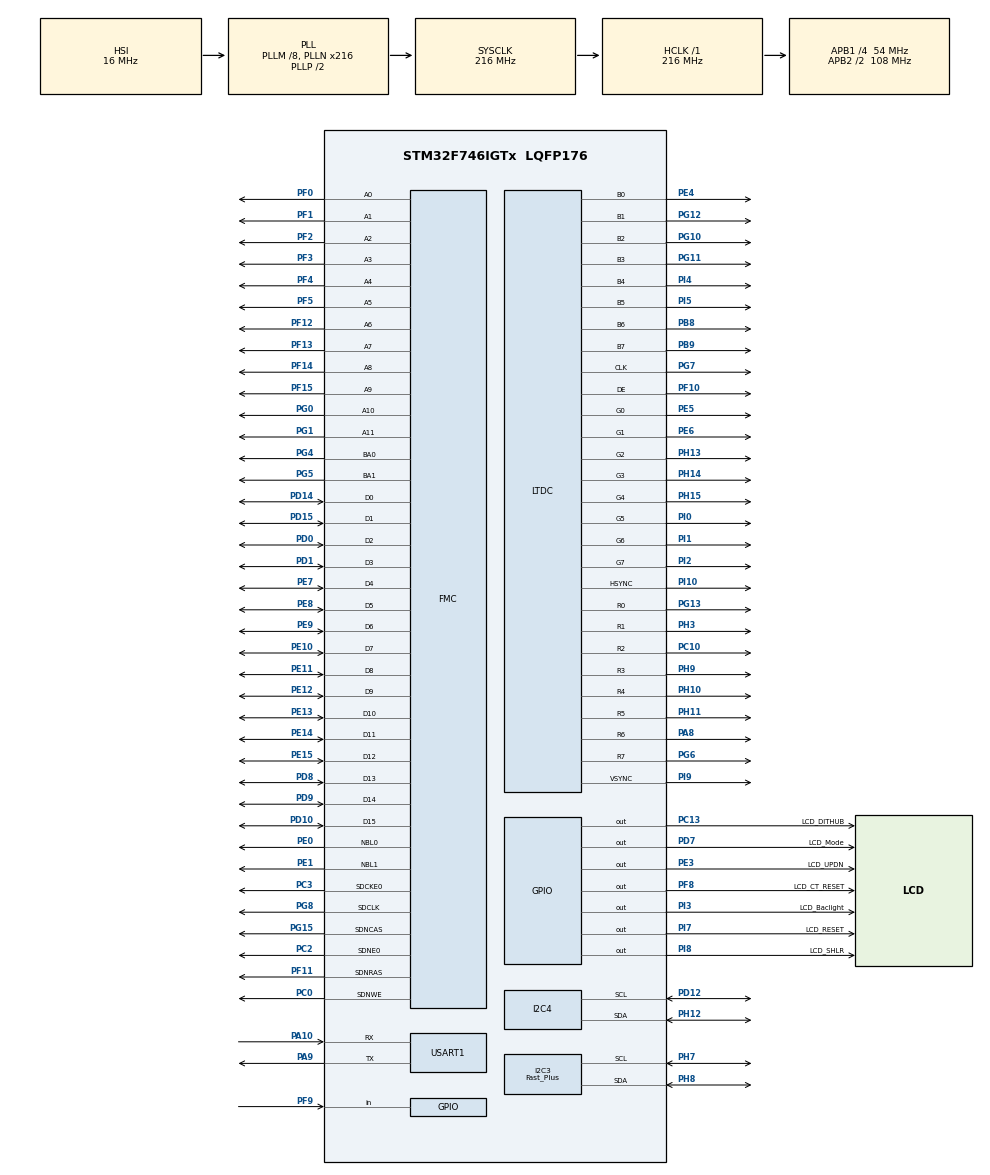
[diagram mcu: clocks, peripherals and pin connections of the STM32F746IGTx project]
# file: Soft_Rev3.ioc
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SH.FMC_D7_DA7.0=FMC_D7,sd-16b-d1
VP_SYS_VS_tim6.Mode=TIM6
FMC.SDClockPeriod2=FMC_SDRAM_CLOCK_PERIOD_2
PH12.Signal=I2C4_SDA
FMC.RCDDelay1=2
FMC.SDClockPeriod1=FMC_SDRAM_CLOCK_PERIOD_2
SH.FMC_A0.0=FMC_A0,12b-sda1
NVIC.TIM6_DAC_IRQn=true\:0\:0\:false\:false\:true\:false\:false\:true
PG8.Signal=FMC_SDCLK
PG4.Signal=FMC_A14_BA0
PG0.Signal=FMC_A10
FMC.LoadToActiveDelay1=2
SH.FMC_D5_DA5.0=FMC_D5,sd-16b-d1
VP_STMicroelectronics.X-CUBE-TOUCHGFX_VS_GraphicsJjApplication_4.16.0.Mode=GraphicsJjApplication
PG6.Mode=RGB888
PG13.Signal=LTDC_R0
PF8.PinState=GPIO_PIN_SET
LTDC.Red=0
RCC.SYSCLKSource=RCC_SYSCLKSOURCE_PLLCLK
SH.FMC_A15_BA1.0=FMC_BA1,FourSdramBanks1
SH.FMC_D9_DA9.0=FMC_D9,sd-16b-d1
STMicroelectronics.X-CUBE-TOUCHGFX.4.16.0.tgfx_hardware_accelerator=dma_2d
FREERTOS.configENABLE_FPU=1
SH.FMC_SDNWE.0=FMC_SDNWE,12b-sda1
PH9.Signal=LTDC_R3
I2C4.Timing=0x20404768
SH.FMC_D11_DA11.0=FMC_D11,sd-16b-d1
RCC.APB2TimFreq_Value=216000000
PH1/OSC_OUT.Signal=RCC_OSC_OUT
PC3.Signal=FMC_SDCKE0
PD0.Signal=FMC_D2_DA2
PD8.Signal=FMC_D13_DA13
PE5.Signal=LTDC_G0
PE1.Signal=FMC_NBL1
FREERTOS.configMINIMAL_STACK_SIZE=254
FMC.SelfRefreshTime1=4
LTDC.PixelFormat_L0=LTDC_PIXEL_FORMAT_RGB565
PF8.GPIO_ModeDefaultOutputPP=GPIO_MODE_OUTPUT_OD
PE9.Signal=FMC_D6_DA6
SH.FMC_A2.0=FMC_A2,12b-sda1
PI3.Signal=GPIO_Output
PA8.Signal=LTDC_R6
SH.FMC_D1_DA1.0=FMC_D1,sd-16b-d1
PF3.Signal=FMC_A3
FMC.WriteProtection1=FMC_SDRAM_WRITE_PROTECTION_DISABLE
PE10.Signal=FMC_D7_DA7
LTDC.HSync=16
PI7.PinState=GPIO_PIN_SET
Mcu.Package=LQFP176
PH10.GPIO_Speed=GPIO_SPEED_FREQ_VERY_HIGH
PB9.Signal=LTDC_B7
PI10.GPIO_Speed=GPIO_SPEED_FREQ_VERY_HIGH
PH12.Mode=I2C
NVIC.TimeBase=TIM6_DAC_IRQn
PH3.GPIO_Speed=GPIO_SPEED_FREQ_VERY_HIGH
PD12.Signal=I2C4_SCL
PI7.GPIO_PuPd=GPIO_PULLUP
PH11.Mode=RGB888
LTDC.Green=0
NVIC.TimeBaseIP=TIM6
PA10.Signal=USART1_RX
FMC.WriteRecoveryTime1=3
SH.FMC_A1.0=FMC_A1,12b-sda1
RCC.APB2CLKDivider=RCC_HCLK_DIV2
SH.FMC_SDCLK.0=FMC_SDCLK,12b-sda1
LTDC.VSync=8
PF14.Signal=FMC_A8
RCC.APB1TimFreq_Value=108000000
VP_DMA2D_VS_DMA2D.Mode=DMA2D_Activate
FMC.RowCycleDelay2=7
PF10.Mode=RGB888
FMC.RowCycleDelay1=7
PH8.Mode=I2C
PE6.GPIO_Speed=GPIO_SPEED_FREQ_VERY_HIGH
PA8.GPIO_Speed=GPIO_SPEED_FREQ_VERY_HIGH
PD15.Signal=FMC_D1_DA1
SH.FMC_D3_DA3.0=FMC_D3,sd-16b-d1
PG6.GPIO_Speed=GPIO_SPEED_FREQ_VERY_HIGH
PG12.Signal=LTDC_B1
SH.FMC_A4.0=FMC_A4,12b-sda1
PH15.Signal=LTDC_G4
FREERTOS.Tasks01=HardwareTask,24,512,StartHardwareTask,Default,NULL,Dynamic,NULL,NULL;TouchGFXTask,24,8192,StartGFXTask,Default,NULL,Dynamic,NULL,NULL
PH13.Signal=LTDC_G2
PI4.Mode=RGB888
PG5.Signal=FMC_A15_BA1
PC13.Signal=GPIO_Output
SH.FMC_D10_DA10.0=FMC_D10,sd-16b-d1
FREERTOS.configCHECK_FOR_STACK_OVERFLOW=2
PI10.Mode=RGB888
PC2.Signal=FMC_SDNE0
PD7.Signal=GPIO_Output
PD1.Signal=FMC_D3_DA3
STMicroelectronics.X-CUBE-TOUCHGFX.4.16.0.tgfx_buffering_strategy=Single
PC0.Signal=FMC_SDNWE
RCC.APB1CLKDivider=RCC_HCLK_DIV4
PI2.Mode=RGB888
PG10.Signal=LTDC_B2
PF8.GPIO_Label=LCD_CT_RESET
LTDC.ImageWidth_L0=1024
PD10.Signal=FMC_D15_DA15
SH.FMC_A3.0=FMC_A3,12b-sda1
PI8.GPIO_Label=LCD_SHLR
FMC.CASLatency1=FMC_SDRAM_CAS_LATENCY_3
PI0.GPIO_Speed=GPIO_SPEED_FREQ_VERY_HIGH
SH.FMC_D15_DA15.0=FMC_D15,sd-16b-d1
PH9.Mode=RGB888
PA9.Signal=USART1_TX
PH14.Mode=RGB888
PI7.Signal=GPIO_Output
FMC.ReadBurst1=FMC_SDRAM_RBURST_DISABLE
SH.FMC_A6.0=FMC_A6,12b-sda1
PE14.Signal=FMC_D11_DA11
LTDC.Blue_L0=0
PE6.Mode=RGB888
PE15.Signal=FMC_D12_DA12
PE8.Signal=FMC_D5_DA5
PI1.Signal=LTDC_G6
PI2.Signal=LTDC_G7
PE3.GPIO_PuPd=GPIO_PULLDOWN
PF13.Signal=FMC_A7
PA13.Mode=Serial_Wire
SH.FMC_SDNCAS.0=FMC_SDNCAS,12b-sda1
PI8.PinState=GPIO_PIN_SET
PD12.Mode=I2C
SH.FMC_A5.0=FMC_A5,12b-sda1
PG11.Mode=RGB888
LTDC.Alpha_L0=255
ProjectManager.HeapSize=0xF000
PG12.GPIO_Speed=GPIO_SPEED_FREQ_VERY_HIGH
PF9.Signal=GPIO_Input
STMicroelectronics.X-CUBE-TOUCHGFX.4.16.0.tgfx_vsync=vsync_ltdc
NVIC.PriorityGroup=NVIC_PRIORITYGROUP_4
PB8.Mode=RGB888
PE3.Signal=GPIO_Output
PC15/OSC32_OUT.Signal=RCC_OSC32_OUT
PA8.Mode=RGB888
PF4.Signal=FMC_A4
LTDC.Alpha0_L0=0
I2C3.I2C_Speed_Mode=I2C_Fast_Plus
Mcu.Family=STM32F7
PC3.Mode=SdramChipSelect1_1
LTDC.BlendingFactor1_L0=LTDC_BLENDING_FACTOR1_CA
SH.FMC_A8.0=FMC_A8,12b-sda1
RCC.CortexFreq_Value=216000000
PG6.Signal=LTDC_R7
PH14.Signal=LTDC_G3
PH10.Signal=LTDC_R4
SH.FMC_D14_DA14.0=FMC_D14,sd-16b-d1
LTDC.HBP=160
PC10.Signal=LTDC_R2
SH.FMC_NBL0.0=FMC_NBL0,Sd2ByteEnable1
SH.FMC_D6_DA6.0=FMC_D6,sd-16b-d1
PC14/OSC32_IN.Mode=LSE-External-Oscillator
PC10.GPIO_Speed=GPIO_SPEED_FREQ_VERY_HIGH
SH.FMC_A14_BA0.0=FMC_BA0,FourSdramBanks1
PH9.GPIO_Speed=GPIO_SPEED_FREQ_VERY_HIGH
SH.FMC_A11.0=FMC_A11,12b-sda1
PI9.GPIO_Speed=GPIO_SPEED_FREQ_VERY_HIGH
PC13.GPIO_Label=LCD_DITHUB
PI2.GPIO_Speed=GPIO_SPEED_FREQ_VERY_HIGH
PI5.Mode=RGB888
PG11.Signal=LTDC_B3
PG15.Signal=FMC_SDNCAS
ProjectManager.StackSize=0x400
VP_FREERTOS_VS_CMSIS_V2.Mode=CMSIS_V2
PH3.Mode=RGB888
PH11.GPIO_Speed=GPIO_SPEED_FREQ_VERY_HIGH
SH.FMC_A7.0=FMC_A7,12b-sda1
STMicroelectronics.X-CUBE-TOUCHGFX.4.16.0.tgfx_location=By Address
PH0/OSC_IN.Mode=HSE-External-Clock-Source
RCC.HCLKFreq_Value=216000000
PH10.Mode=RGB888
SH.FMC_NBL1.0=FMC_NBL1,Sd2ByteEnable1
LTDC.WindowX1_L0=1024
PF12.Signal=FMC_A6
PI9.Mode=RGB888
PH13.GPIO_Speed=GPIO_SPEED_FREQ_VERY_HIGH
SH.FMC_A10.0=FMC_A10,12b-sda1
RCC.AHBFreq_Value=216000000
I2C3.Speed=400
RCC.HSE_VALUE=25000000
STMicroelectronics.X-CUBE-TOUCHGFX.4.16.0.tgfx_display_interface=disp_ltdc
SH.FMC_D8_DA8.0=FMC_D8,sd-16b-d1
FMC.ExitSelfRefreshDelay1=7
FMC.RPDelay1=2
PI8.Signal=GPIO_Output
SH.FMC_D2_DA2.0=FMC_D2,sd-16b-d1
PG11.GPIO_Speed=GPIO_SPEED_FREQ_VERY_HIGH
LTDC.VBP=23
PE13.Signal=FMC_D10_DA10
PF8.GPIO_PuPd=GPIO_PULLUP
PA14.Mode=Serial_Wire
PI5.Signal=LTDC_B5
PE4.GPIO_Speed=GPIO_SPEED_FREQ_VERY_HIGH
PI4.GPIO_Speed=GPIO_SPEED_FREQ_VERY_HIGH
PI0.Signal=LTDC_G5
PF11.Signal=FMC_SDNRAS
PI8.GPIO_PuPd=GPIO_PULLDOWN
PC13.GPIO_PuPd=GPIO_PULLDOWN
LTDC.HFP=160
LTDC.BlendingFactor2_L0=LTDC_BLENDING_FACTOR2_CA
PG13.Mode=RGB888
FMC.ReadPipeDelay1=FMC_SDRAM_RPIPE_DELAY_0
PE4.Mode=RGB888
SH.FMC_SDNRAS.0=FMC_SDNRAS,12b-sda1
DMA2D.ColorMode=DMA2D_OUTPUT_RGB565
LTDC.ActiveW=1024
PH1/OSC_OUT.Mode=HSE-External-Clock-Source
PE4.Signal=LTDC_B0
FREERTOS.configTOTAL_HEAP_SIZE=50000
STMicroelectronics.X-CUBE-TOUCHGFX.4.16.0.tgfx_address1=0xC0000000
STMicroelectronics.X-CUBE-TOUCHGFX.4.16.0.tgfx_address2=0xC01C2000
PH7.Mode=I2C
PD7.GPIO_Label=LCD_Mode
SH.FMC_D0_DA0.0=FMC_D0,sd-16b-d1
PC14/OSC32_IN.Signal=RCC_OSC32_IN
SH.FMC_A9.0=FMC_A9,12b-sda1
PF8.Signal=GPIO_Output
SH.FMC_D4_DA4.0=FMC_D4,sd-16b-d1
PI1.Mode=RGB888
RCC.PLLSAIN=100
PF5.Signal=FMC_A5
RCC.PLLSAIR=4
PH7.Signal=I2C3_SCL
I2C3.Timing=0x00200D6F
PB9.GPIO_Speed=GPIO_SPEED_FREQ_VERY_HIGH
PG13.GPIO_Speed=GPIO_SPEED_FREQ_VERY_HIGH
PF0.Signal=FMC_A0
PE7.Signal=FMC_D4_DA4
PC13.PinState=GPIO_PIN_SET
PH15.GPIO_Speed=GPIO_SPEED_FREQ_VERY_HIGH
NVIC.LTDC_IRQn=true\:5\:0\:false\:false\:true\:true\:true\:true
LTDC.FBStartAdress_L0=0xC0000000
LTDC.VFP=12
LTDC.WindowY1_L0=600
PG7.Signal=LTDC_CLK
PA10.Mode=Asynchronous
PH11.Signal=LTDC_R5
PG1.Signal=FMC_A11
PF10.GPIO_Speed=GPIO_SPEED_FREQ_VERY_HIGH
PC10.Mode=RGB888
PG10.Mode=RGB888
PC2.Mode=SdramChipSelect1_1
PI10.Signal=LTDC_HSYNC
PD9.Signal=FMC_D14_DA14
PG10.GPIO_Speed=GPIO_SPEED_FREQ_VERY_HIGH
USART1.VirtualMode-Asynchronous=VM_ASYNC
PA13.Signal=SYS_JTMS-SWDIO
PA9.Mode=Asynchronous
ProjectManager.TargetToolchain=STM32CubeIDE
SH.FMC_D13_DA13.0=FMC_D13,sd-16b-d1
LTDC.ActiveH=600
PH8.Signal=I2C3_SDA
PI0.Mode=RGB888
PB9.Mode=RGB888
PF2.Signal=FMC_A2
STMicroelectronics.X-CUBE-TOUCHGFX.4.16.0.ApplicationCcGraphicsJjApplication=TouchGFXOoGenerator
RCC.USBFreq_Value=216000000
PH13.Mode=RGB888
PG7.Mode=RGB888
PE11.Signal=FMC_D8_DA8
PH14.GPIO_Speed=GPIO_SPEED_FREQ_VERY_HIGH
board=custom
PG12.Mode=RGB888
RCC.VCOOutputFreq_Value=432000000
PI9.Signal=LTDC_VSYNC
PH0/OSC_IN.Signal=RCC_OSC_IN
PG7.GPIO_Speed=GPIO_SPEED_FREQ_VERY_HIGH
RCC.APB2Freq_Value=108000000
LTDC.Layers=0
PF10.Signal=LTDC_DE
PI4.Signal=LTDC_B4
PE5.Mode=RGB888
SH.FMC_D12_DA12.0=FMC_D12,sd-16b-d1
PI7.GPIO_Label=LCD_RESET
PF15.Signal=FMC_A9
PF1.Signal=FMC_A1
PI1.GPIO_Speed=GPIO_SPEED_FREQ_VERY_HIGH
PE6.Signal=LTDC_G1
Mcu.Name=STM32F746IGTx
PE0.Signal=FMC_NBL0
PE12.Signal=FMC_D9_DA9
PH15.Mode=RGB888
PD14.Signal=FMC_D0_DA0
RCC.SYSCLKFreq_VALUE=216000000
PC15/OSC32_OUT.Mode=LSE-External-Oscillator
PA14.Signal=SYS_JTCK-SWCLK
RCC.HSI_VALUE=16000000
PH3.Signal=LTDC_R1
PI3.GPIO_Label=LCD_Baclight
RCC.PLLM=8
RCC.PLLN=216
PE5.GPIO_Speed=GPIO_SPEED_FREQ_VERY_HIGH
PB8.Signal=LTDC_B6
PE3.GPIO_Label=LCD_UPDN
CORTEX_M7.CPU_DCache=Enabled
RCC.APB1Freq_Value=54000000
PB8.GPIO_Speed=GPIO_SPEED_FREQ_VERY_HIGH
VP_CRC_VS_CRC.Mode=CRC_Activate
LTDC.ImageHeight_L0=600
PI5.GPIO_Speed=GPIO_SPEED_FREQ_VERY_HIGH

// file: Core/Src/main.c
/* USER CODE BEGIN Header */
/**
  ******************************************************************************
  * @file           : main.c
  * @brief          : Main program body
  ******************************************************************************
  * @attention
  *
  * <h2><center>&copy; Copyright (c) 2021 STMicroelectronics.
  * All rights reserved.</center></h2>
  *
  * This software component is licensed by ST under BSD 3-Clause license,
  * the "License"; You may not use this file except in compliance with the
  * License. You may obtain a copy of the License at:
  *                        opensource.org/licenses/BSD-3-Clause
  *
  ******************************************************************************
  */
/* USER CODE END Header */
#include "main.h"
#include "cmsis_os.h"
#include "app_touchgfx.h"

/* USER CODE BEGIN PD */
#define IS42S16400J_SIZE 0x400000
#define SDRAM_REFRESH_COUNT 1539
#define SDRAM_ADDR 0xC0000000
#define SDRAM_ADDR_SWP 0x80000000
#define SDRAM_BANK FMC_Bank1_SDRAM

#define SDRAM_TIMEOUT 								((uint32_t)0xFFFF)
#define SDRAM_MODEREG_BURST_LENGTH_1 				((uint16_t)0x0000)
#define SDRAM_MODEREG_BURST_LENGTH_2 				((uint16_t)0x0001)
#define SDRAM_MODEREG_BURST_LENGTH_4 				((uint16_t)0x0002)
#define SDRAM_MODEREG_BURST_LENGTH_8 				((uint16_t)0x0003)
#define SDRAM_MODEREG_BURST_TYPE_SEQUENTIAL 		((uint16_t)0x0007)
#define SDRAM_MODEREG_BURST_TYPE_INTERLEAVED 		((uint16_t)0x0008)
#define SDRAM_MODEREG_CAS_LATENCY_2 				((uint16_t)0x0020)
#define SDRAM_MODEREG_CAS_LATENCY_3 				((uint16_t)0x0030)
#define SDRAM_MODEREG_OPERATING_MODE_STANDARD 		((uint16_t)0x0000)
#define SDRAM_MODEREG_WRITEBURST_MODE_PROGRAMMED 	((uint16_t)0x0000)
#define SDRAM_MODEREG_WRITEBURST_MODE_SINGLE 		((uint16_t)0x0200)

#define WRITE_SDRAM_32(address, word) (*( uint32_t*) (address + 4)) = word

/* LCD Defines And Vars */

#define DisplayBufferLenght 1024*600*3
uint16_t* framebuffer = (uint16_t*)0xC0000000;

/* USER CODE END PD */

CRC_HandleTypeDef hcrc;

DMA2D_HandleTypeDef hdma2d;

I2C_HandleTypeDef hi2c3;
I2C_HandleTypeDef hi2c4;

LTDC_HandleTypeDef hltdc;

UART_HandleTypeDef huart1;

SDRAM_HandleTypeDef hsdram1;

/* Definitions for HardwareTask */
osThreadId_t HardwareTaskHandle;
const osThreadAttr_t HardwareTask_attributes = {
  .name = "HardwareTask",
  .stack_size = 512 * 4,
  .priority = (osPriority_t) osPriorityNormal,
};
/* Definitions for TouchGFXTask */
osThreadId_t TouchGFXTaskHandle;
const osThreadAttr_t TouchGFXTask_attributes = {
  .name = "TouchGFXTask",
  .stack_size = 8192 * 4,
  .priority = (osPriority_t) osPriorityNormal,
};

void SystemClock_Config(void);
static void MX_GPIO_Init(void);
static void MX_LTDC_Init(void);
static void MX_FMC_Init(void);
static void MX_DMA2D_Init(void);
static void MX_CRC_Init(void);
static void MX_I2C3_Init(void);
static void MX_USART1_UART_Init(void);
static void MX_I2C4_Init(void);
void StartHardwareTask(void *argument);
void StartGFXTask(void *argument);

/* USER CODE BEGIN 0 */

#include <errno.h>
#include <sys/stat.h>
#include <sys/times.h>
#include <sys/unistd.h>
int _write(int file, char *ptr, int len) {
    HAL_StatusTypeDef xStatus;
    switch (file) {
    case STDOUT_FILENO: /*stdout*/
		xStatus = HAL_UART_Transmit(&huart1, (uint8_t*)ptr, len, HAL_MAX_DELAY);
		if (xStatus != HAL_OK) {
			errno = EIO;
			return -1;
		}
        break;
    case STDERR_FILENO: /* stderr */
		xStatus = HAL_UART_Transmit(&huart1, (uint8_t*)ptr, len, HAL_MAX_DELAY);
		if (xStatus != HAL_OK) {
			errno = EIO;
			return -1;
		}
        break;
    default:
        errno = EBADF;
        return -1;
    }
    return len;
}

void twiScan(void)
{
uint8_t Buffer[25] = {0};
uint8_t Space[] = " - ";
uint8_t StartMSG[] = "Starting I2C Scanning: \r\n";
uint8_t EndMSG[] = "Done! \r\n\r\n";

uint8_t i = 0, ret;

HAL_Delay(1000);
/*-[ I2C Bus Scanning ]-*/
HAL_UART_Transmit(&huart1, StartMSG, sizeof(StartMSG), 10000);
for(i=1; i<128; i++)
{
	ret = HAL_I2C_IsDeviceReady(&hi2c4, (uint16_t)(i<<1), 3, 5);
	if (ret != HAL_OK) /* No ACK Received At That Address */
	{
	    HAL_UART_Transmit(&huart1, Space, sizeof(Space), 10000);
    }
	else if(ret == HAL_OK)
	{
	    sprintf(Buffer, "0x%X", i);
	    HAL_UART_Transmit(&huart1, Buffer, sizeof(Buffer), 10000);
	}
}
HAL_UART_Transmit(&huart1, EndMSG, sizeof(EndMSG), 10000);
/*--[ Scanning Done ]--*/
}

/* USER CODE END 0 */

int main(void)
{

  /* Enable D-Cache---------------------------------------------------------*/
  SCB_EnableDCache();

  /* MCU Configuration--------------------------------------------------------*/

  /* Reset of all peripherals, Initializes the Flash interface and the Systick. */
  HAL_Init();

  /* Configure the system clock */
  SystemClock_Config();

  /* Initialize all configured peripherals */
  MX_GPIO_Init();
  MX_LTDC_Init();
  MX_FMC_Init();
  MX_DMA2D_Init();
  MX_CRC_Init();
  MX_I2C3_Init();
  MX_USART1_UART_Init();
  MX_I2C4_Init();
  MX_TouchGFX_Init();
  /* USER CODE BEGIN 2 */

  HAL_Delay(300);
  HAL_GPIO_WritePin(LCD_Baclight_GPIO_Port,LCD_Baclight_Pin,GPIO_PIN_SET);
  //uint32_t* framebuffer = (uint32_t*)0xC0000000;
  //Clear LCD buffer
  //for(uint32_t i = 0;i < 160000;i++){
  //	 framebuffer[i] = i;
  //	HAL_Delay(1);
  //}
  HAL_Delay(1000);
  //twiScan();
  uint16_t X,Y;
  uint8_t Pressure,Touch;
  /* USER CODE END 2 */

  /* Init scheduler */
  osKernelInitialize();

  /* Create the thread(s) */
  /* creation of HardwareTask */
  HardwareTaskHandle = osThreadNew(StartHardwareTask, NULL, &HardwareTask_attributes);

  /* creation of TouchGFXTask */
  TouchGFXTaskHandle = osThreadNew(StartGFXTask, NULL, &TouchGFXTask_attributes);

  /* Start scheduler */
  osKernelStart();

  /* We should never get here as control is now taken by the scheduler */
  /* Infinite loop */
  while (1)
  {

    /* USER CODE BEGIN 3 */

  //GetTouchPoint(&hi2c3,0x38,1,&X,&Y,&Touch,&Pressure);

  }
  /* USER CODE END 3 */
}

void SystemClock_Config(void)
{
  RCC_OscInitTypeDef RCC_OscInitStruct = {0};
  RCC_ClkInitTypeDef RCC_ClkInitStruct = {0};
  RCC_PeriphCLKInitTypeDef PeriphClkInitStruct = {0};

  /** Configure LSE Drive Capability
  */
  HAL_PWR_EnableBkUpAccess();
  /** Configure the main internal regulator output voltage
  */
  __HAL_RCC_PWR_CLK_ENABLE();
  __HAL_PWR_VOLTAGESCALING_CONFIG(PWR_REGULATOR_VOLTAGE_SCALE1);
  /** Initializes the RCC Oscillators according to the specified parameters
  * in the RCC_OscInitTypeDef structure.
  */
  RCC_OscInitStruct.OscillatorType = RCC_OSCILLATORTYPE_HSI;
  RCC_OscInitStruct.HSIState = RCC_HSI_ON;
  RCC_OscInitStruct.HSICalibrationValue = RCC_HSICALIBRATION_DEFAULT;
  RCC_OscInitStruct.PLL.PLLState = RCC_PLL_ON;
  RCC_OscInitStruct.PLL.PLLSource = RCC_PLLSOURCE_HSI;
  RCC_OscInitStruct.PLL.PLLM = 8;
  RCC_OscInitStruct.PLL.PLLN = 216;
  RCC_OscInitStruct.PLL.PLLP = RCC_PLLP_DIV2;
  RCC_OscInitStruct.PLL.PLLQ = 2;
  if (HAL_RCC_OscConfig(&RCC_OscInitStruct) != HAL_OK)
  {
    Error_Handler();
  }
  /** Activate the Over-Drive mode
  */
  if (HAL_PWREx_EnableOverDrive() != HAL_OK)
  {
    Error_Handler();
  }
  /** Initializes the CPU, AHB and APB buses clocks
  */
  RCC_ClkInitStruct.ClockType = RCC_CLOCKTYPE_HCLK|RCC_CLOCKTYPE_SYSCLK
                              |RCC_CLOCKTYPE_PCLK1|RCC_CLOCKTYPE_PCLK2;
  RCC_ClkInitStruct.SYSCLKSource = RCC_SYSCLKSOURCE_PLLCLK;
  RCC_ClkInitStruct.AHBCLKDivider = RCC_SYSCLK_DIV1;
  RCC_ClkInitStruct.APB1CLKDivider = RCC_HCLK_DIV4;
  RCC_ClkInitStruct.APB2CLKDivider = RCC_HCLK_DIV2;

  if (HAL_RCC_ClockConfig(&RCC_ClkInitStruct, FLASH_LATENCY_7) != HAL_OK)
  {
    Error_Handler();
  }
  PeriphClkInitStruct.PeriphClockSelection = RCC_PERIPHCLK_LTDC|RCC_PERIPHCLK_USART1
                              |RCC_PERIPHCLK_I2C3|RCC_PERIPHCLK_I2C4;
  PeriphClkInitStruct.PLLSAI.PLLSAIN = 100;
  PeriphClkInitStruct.PLLSAI.PLLSAIR = 4;
  PeriphClkInitStruct.PLLSAI.PLLSAIQ = 2;
  PeriphClkInitStruct.PLLSAI.PLLSAIP = RCC_PLLSAIP_DIV2;
  PeriphClkInitStruct.PLLSAIDivQ = 1;
  PeriphClkInitStruct.PLLSAIDivR = RCC_PLLSAIDIVR_2;
  PeriphClkInitStruct.Usart1ClockSelection = RCC_USART1CLKSOURCE_PCLK2;
  PeriphClkInitStruct.I2c3ClockSelection = RCC_I2C3CLKSOURCE_PCLK1;
  PeriphClkInitStruct.I2c4ClockSelection = RCC_I2C4CLKSOURCE_PCLK1;
  if (HAL_RCCEx_PeriphCLKConfig(&PeriphClkInitStruct) != HAL_OK)
  {
    Error_Handler();
  }
}

static void MX_CRC_Init(void)
{

  hcrc.Instance = CRC;
  hcrc.Init.DefaultPolynomialUse = DEFAULT_POLYNOMIAL_ENABLE;
  hcrc.Init.DefaultInitValueUse = DEFAULT_INIT_VALUE_ENABLE;
  hcrc.Init.InputDataInversionMode = CRC_INPUTDATA_INVERSION_NONE;
  hcrc.Init.OutputDataInversionMode = CRC_OUTPUTDATA_INVERSION_DISABLE;
  hcrc.InputDataFormat = CRC_INPUTDATA_FORMAT_BYTES;
  if (HAL_CRC_Init(&hcrc) != HAL_OK)
  {
    Error_Handler();
  }

}

static void MX_DMA2D_Init(void)
{

  hdma2d.Instance = DMA2D;
  hdma2d.Init.Mode = DMA2D_M2M;
  hdma2d.Init.ColorMode = DMA2D_OUTPUT_RGB565;
  hdma2d.Init.OutputOffset = 0;
  hdma2d.LayerCfg[1].InputOffset = 0;
  hdma2d.LayerCfg[1].InputColorMode = DMA2D_INPUT_RGB565;
  hdma2d.LayerCfg[1].AlphaMode = DMA2D_NO_MODIF_ALPHA;
  hdma2d.LayerCfg[1].InputAlpha = 0;
  if (HAL_DMA2D_Init(&hdma2d) != HAL_OK)
  {
    Error_Handler();
  }
  if (HAL_DMA2D_ConfigLayer(&hdma2d, 1) != HAL_OK)
  {
    Error_Handler();
  }

}

static void MX_I2C3_Init(void)
{

  hi2c3.Instance = I2C3;
  hi2c3.Init.Timing = 0x00200D6F;
  hi2c3.Init.OwnAddress1 = 0;
  hi2c3.Init.AddressingMode = I2C_ADDRESSINGMODE_7BIT;
  hi2c3.Init.DualAddressMode = I2C_DUALADDRESS_DISABLE;
  hi2c3.Init.OwnAddress2 = 0;
  hi2c3.Init.OwnAddress2Masks = I2C_OA2_NOMASK;
  hi2c3.Init.GeneralCallMode = I2C_GENERALCALL_DISABLE;
  hi2c3.Init.NoStretchMode = I2C_NOSTRETCH_DISABLE;
  if (HAL_I2C_Init(&hi2c3) != HAL_OK)
  {
    Error_Handler();
  }
  /** Configure Analogue filter
  */
  if (HAL_I2CEx_ConfigAnalogFilter(&hi2c3, I2C_ANALOGFILTER_ENABLE) != HAL_OK)
  {
    Error_Handler();
  }
  /** Configure Digital filter
  */
  if (HAL_I2CEx_ConfigDigitalFilter(&hi2c3, 0) != HAL_OK)
  {
    Error_Handler();
  }
  /** I2C Enable Fast Mode Plus
  */
  HAL_I2CEx_EnableFastModePlus(I2C_FASTMODEPLUS_I2C3);

}

static void MX_I2C4_Init(void)
{

  hi2c4.Instance = I2C4;
  hi2c4.Init.Timing = 0x20404768;
  hi2c4.Init.OwnAddress1 = 0;
  hi2c4.Init.AddressingMode = I2C_ADDRESSINGMODE_7BIT;
  hi2c4.Init.DualAddressMode = I2C_DUALADDRESS_DISABLE;
  hi2c4.Init.OwnAddress2 = 0;
  hi2c4.Init.OwnAddress2Masks = I2C_OA2_NOMASK;
  hi2c4.Init.GeneralCallMode = I2C_GENERALCALL_DISABLE;
  hi2c4.Init.NoStretchMode = I2C_NOSTRETCH_DISABLE;
  if (HAL_I2C_Init(&hi2c4) != HAL_OK)
  {
    Error_Handler();
  }
  /** Configure Analogue filter
  */
  if (HAL_I2CEx_ConfigAnalogFilter(&hi2c4, I2C_ANALOGFILTER_ENABLE) != HAL_OK)
  {
    Error_Handler();
  }
  /** Configure Digital filter
  */
  if (HAL_I2CEx_ConfigDigitalFilter(&hi2c4, 0) != HAL_OK)
  {
    Error_Handler();
  }

}

static void MX_LTDC_Init(void)
{

  LTDC_LayerCfgTypeDef pLayerCfg = {0};

  hltdc.Instance = LTDC;
  hltdc.Init.HSPolarity = LTDC_HSPOLARITY_AL;
  hltdc.Init.VSPolarity = LTDC_VSPOLARITY_AL;
  hltdc.Init.DEPolarity = LTDC_DEPOLARITY_AL;
  hltdc.Init.PCPolarity = LTDC_PCPOLARITY_IPC;
  hltdc.Init.HorizontalSync = 15;
  hltdc.Init.VerticalSync = 7;
  hltdc.Init.AccumulatedHBP = 175;
  hltdc.Init.AccumulatedVBP = 30;
  hltdc.Init.AccumulatedActiveW = 1199;
  hltdc.Init.AccumulatedActiveH = 630;
  hltdc.Init.TotalWidth = 1359;
  hltdc.Init.TotalHeigh = 642;
  hltdc.Init.Backcolor.Blue = 0;
  hltdc.Init.Backcolor.Green = 0;
  hltdc.Init.Backcolor.Red = 0;
  if (HAL_LTDC_Init(&hltdc) != HAL_OK)
  {
    Error_Handler();
  }
  pLayerCfg.WindowX0 = 0;
  pLayerCfg.WindowX1 = 1024;
  pLayerCfg.WindowY0 = 0;
  pLayerCfg.WindowY1 = 600;
  pLayerCfg.PixelFormat = LTDC_PIXEL_FORMAT_RGB565;
  pLayerCfg.Alpha = 255;
  pLayerCfg.Alpha0 = 0;
  pLayerCfg.BlendingFactor1 = LTDC_BLENDING_FACTOR1_CA;
  pLayerCfg.BlendingFactor2 = LTDC_BLENDING_FACTOR2_CA;
  pLayerCfg.FBStartAdress = 0xC0000000;
  pLayerCfg.ImageWidth = 1024;
  pLayerCfg.ImageHeight = 600;
  pLayerCfg.Backcolor.Blue = 0;
  pLayerCfg.Backcolor.Green = 0;
  pLayerCfg.Backcolor.Red = 0;
  if (HAL_LTDC_ConfigLayer(&hltdc, &pLayerCfg, 0) != HAL_OK)
  {
    Error_Handler();
  }

}

static void MX_USART1_UART_Init(void)
{

  huart1.Instance = USART1;
  huart1.Init.BaudRate = 115200;
  huart1.Init.WordLength = UART_WORDLENGTH_8B;
  huart1.Init.StopBits = UART_STOPBITS_1;
  huart1.Init.Parity = UART_PARITY_NONE;
  huart1.Init.Mode = UART_MODE_TX_RX;
  huart1.Init.HwFlowCtl = UART_HWCONTROL_NONE;
  huart1.Init.OverSampling = UART_OVERSAMPLING_16;
  huart1.Init.OneBitSampling = UART_ONE_BIT_SAMPLE_DISABLE;
  huart1.AdvancedInit.AdvFeatureInit = UART_ADVFEATURE_NO_INIT;
  if (HAL_UART_Init(&huart1) != HAL_OK)
  {
    Error_Handler();
  }

}

/* FMC initialization function */
static void MX_FMC_Init(void)
{

  FMC_SDRAM_TimingTypeDef SdramTiming = {0};

  /** Perform the SDRAM1 memory initialization sequence
  */
  hsdram1.Instance = FMC_SDRAM_DEVICE;
  /* hsdram1.Init */
  hsdram1.Init.SDBank = FMC_SDRAM_BANK1;
  hsdram1.Init.ColumnBitsNumber = FMC_SDRAM_COLUMN_BITS_NUM_8;
  hsdram1.Init.RowBitsNumber = FMC_SDRAM_ROW_BITS_NUM_12;
  hsdram1.Init.MemoryDataWidth = FMC_SDRAM_MEM_BUS_WIDTH_16;
  hsdram1.Init.InternalBankNumber = FMC_SDRAM_INTERN_BANKS_NUM_4;
  hsdram1.Init.CASLatency = FMC_SDRAM_CAS_LATENCY_3;
  hsdram1.Init.WriteProtection = FMC_SDRAM_WRITE_PROTECTION_DISABLE;
  hsdram1.Init.SDClockPeriod = FMC_SDRAM_CLOCK_PERIOD_2;
  hsdram1.Init.ReadBurst = FMC_SDRAM_RBURST_DISABLE;
  hsdram1.Init.ReadPipeDelay = FMC_SDRAM_RPIPE_DELAY_0;
  /* SdramTiming */
  SdramTiming.LoadToActiveDelay = 2;
  SdramTiming.ExitSelfRefreshDelay = 7;
  SdramTiming.SelfRefreshTime = 4;
  SdramTiming.RowCycleDelay = 7;
  SdramTiming.WriteRecoveryTime = 3;
  SdramTiming.RPDelay = 2;
  SdramTiming.RCDDelay = 2;

  if (HAL_SDRAM_Init(&hsdram1, &SdramTiming) != HAL_OK)
  {
    Error_Handler( );
  }

  /* USER CODE BEGIN FMC_Init 2 */
  MX_SDRAM_InitSeqeunce(SDRAM_REFRESH_COUNT,SDRAM_TIMEOUT);
  /* USER CODE END FMC_Init 2 */
}

static void MX_GPIO_Init(void)
{
  GPIO_InitTypeDef GPIO_InitStruct = {0};

  /* GPIO Ports Clock Enable */
  __HAL_RCC_GPIOE_CLK_ENABLE();
  __HAL_RCC_GPIOI_CLK_ENABLE();
  __HAL_RCC_GPIOC_CLK_ENABLE();
  __HAL_RCC_GPIOF_CLK_ENABLE();
  __HAL_RCC_GPIOH_CLK_ENABLE();
  __HAL_RCC_GPIOG_CLK_ENABLE();
  __HAL_RCC_GPIOD_CLK_ENABLE();
  __HAL_RCC_GPIOA_CLK_ENABLE();
  __HAL_RCC_GPIOB_CLK_ENABLE();

  /*Configure GPIO pin Output Level */
  HAL_GPIO_WritePin(LCD_UPDN_GPIO_Port, LCD_UPDN_Pin, GPIO_PIN_RESET);

  /*Configure GPIO pin Output Level */
  HAL_GPIO_WritePin(GPIOI, LCD_SHLR_Pin|LCD_RESET_Pin, GPIO_PIN_SET);

  /*Configure GPIO pin Output Level */
  HAL_GPIO_WritePin(LCD_DITHUB_GPIO_Port, LCD_DITHUB_Pin, GPIO_PIN_SET);

  /*Configure GPIO pin Output Level */
  HAL_GPIO_WritePin(LCD_CT_RESET_GPIO_Port, LCD_CT_RESET_Pin, GPIO_PIN_SET);

  /*Configure GPIO pin Output Level */
  HAL_GPIO_WritePin(LCD_Baclight_GPIO_Port, LCD_Baclight_Pin, GPIO_PIN_RESET);

  /*Configure GPIO pin Output Level */
  HAL_GPIO_WritePin(LCD_Mode_GPIO_Port, LCD_Mode_Pin, GPIO_PIN_RESET);

  /*Configure GPIO pin : LCD_UPDN_Pin */
  GPIO_InitStruct.Pin = LCD_UPDN_Pin;
  GPIO_InitStruct.Mode = GPIO_MODE_OUTPUT_PP;
  GPIO_InitStruct.Pull = GPIO_PULLDOWN;
  GPIO_InitStruct.Speed = GPIO_SPEED_FREQ_LOW;
  HAL_GPIO_Init(LCD_UPDN_GPIO_Port, &GPIO_InitStruct);

  /*Configure GPIO pin : LCD_SHLR_Pin */
  GPIO_InitStruct.Pin = LCD_SHLR_Pin;
  GPIO_InitStruct.Mode = GPIO_MODE_OUTPUT_PP;
  GPIO_InitStruct.Pull = GPIO_PULLDOWN;
  GPIO_InitStruct.Speed = GPIO_SPEED_FREQ_LOW;
  HAL_GPIO_Init(LCD_SHLR_GPIO_Port, &GPIO_InitStruct);

  /*Configure GPIO pin : LCD_DITHUB_Pin */
  GPIO_InitStruct.Pin = LCD_DITHUB_Pin;
  GPIO_InitStruct.Mode = GPIO_MODE_OUTPUT_PP;
  GPIO_InitStruct.Pull = GPIO_PULLDOWN;
  GPIO_InitStruct.Speed = GPIO_SPEED_FREQ_LOW;
  HAL_GPIO_Init(LCD_DITHUB_GPIO_Port, &GPIO_InitStruct);

  /*Configure GPIO pin : LCD_CT_RESET_Pin */
  GPIO_InitStruct.Pin = LCD_CT_RESET_Pin;
  GPIO_InitStruct.Mode = GPIO_MODE_OUTPUT_OD;
  GPIO_InitStruct.Pull = GPIO_PULLUP;
  GPIO_InitStruct.Speed = GPIO_SPEED_FREQ_LOW;
  HAL_GPIO_Init(LCD_CT_RESET_GPIO_Port, &GPIO_InitStruct);

  /*Configure GPIO pin : PF9 */
  GPIO_InitStruct.Pin = GPIO_PIN_9;
  GPIO_InitStruct.Mode = GPIO_MODE_INPUT;
  GPIO_InitStruct.Pull = GPIO_NOPULL;
  HAL_GPIO_Init(GPIOF, &GPIO_InitStruct);

  /*Configure GPIO pin : LCD_Baclight_Pin */
  GPIO_InitStruct.Pin = LCD_Baclight_Pin;
  GPIO_InitStruct.Mode = GPIO_MODE_OUTPUT_PP;
  GPIO_InitStruct.Pull = GPIO_NOPULL;
  GPIO_InitStruct.Speed = GPIO_SPEED_FREQ_LOW;
  HAL_GPIO_Init(LCD_Baclight_GPIO_Port, &GPIO_InitStruct);

  /*Configure GPIO pin : LCD_Mode_Pin */
  GPIO_InitStruct.Pin = LCD_Mode_Pin;
  GPIO_InitStruct.Mode = GPIO_MODE_OUTPUT_PP;
  GPIO_InitStruct.Pull = GPIO_NOPULL;
  GPIO_InitStruct.Speed = GPIO_SPEED_FREQ_LOW;
  HAL_GPIO_Init(LCD_Mode_GPIO_Port, &GPIO_InitStruct);

  /*Configure GPIO pin : LCD_RESET_Pin */
  GPIO_InitStruct.Pin = LCD_RESET_Pin;
  GPIO_InitStruct.Mode = GPIO_MODE_OUTPUT_PP;
  GPIO_InitStruct.Pull = GPIO_PULLUP;
  GPIO_InitStruct.Speed = GPIO_SPEED_FREQ_LOW;
  HAL_GPIO_Init(LCD_RESET_GPIO_Port, &GPIO_InitStruct);

}

/* USER CODE BEGIN 4 */

void MX_SDRAM_InitSeqeunce(uint32_t RefreshCount,uint32_t timout){
	__IO uint32_t tmpmrd = 0;
	static FMC_SDRAM_CommandTypeDef Command;

	Command.CommandMode 			= FMC_SDRAM_CMD_CLK_ENABLE;
	Command.CommandTarget  			= FMC_SDRAM_CMD_TARGET_BANK1;
	Command.AutoRefreshNumber		= 1;
	Command.ModeRegisterDefinition 	= 0;

	HAL_SDRAM_SendCommand(&hsdram1, &Command, timout);

	HAL_Delay(1);

	Command.CommandMode 			= FMC_SDRAM_CMD_PALL;
	Command.CommandTarget  			= FMC_SDRAM_CMD_TARGET_BANK1;
	Command.AutoRefreshNumber		= 1;
	Command.ModeRegisterDefinition 	= 0;

	HAL_SDRAM_SendCommand(&hsdram1, &Command, timout);

	Command.CommandMode 			= FMC_SDRAM_CMD_AUTOREFRESH_MODE;
	Command.CommandTarget  			= FMC_SDRAM_CMD_TARGET_BANK1;
	Command.AutoRefreshNumber		= 8;
	Command.ModeRegisterDefinition 	= 0;

	HAL_SDRAM_SendCommand(&hsdram1, &Command, timout);

    tmpmrd = (uint32_t)SDRAM_MODEREG_BURST_LENGTH_1          |
					   SDRAM_MODEREG_BURST_TYPE_SEQUENTIAL   |
					   SDRAM_MODEREG_CAS_LATENCY_3           |
					   SDRAM_MODEREG_WRITEBURST_MODE_SINGLE;

	Command.CommandMode 			= FMC_SDRAM_CMD_LOAD_MODE;
	Command.CommandTarget  			= FMC_SDRAM_CMD_TARGET_BANK1;
	Command.AutoRefreshNumber		= 1;
	Command.ModeRegisterDefinition 	= tmpmrd;

	HAL_SDRAM_SendCommand(&hsdram1, &Command, timout);

	HAL_SDRAM_ProgramRefreshRate(&hsdram1, RefreshCount);
}
/* USER CODE END 4 */

void StartHardwareTask(void *argument)
{
  /* USER CODE BEGIN 5 */
  /* Infinite loop */
  for(;;)
  {
    osDelay(100);
  }
  /* USER CODE END 5 */
}

void StartGFXTask(void *argument)
{
  /* USER CODE BEGIN StartGFXTask */

  MX_TouchGFX_Process();
  /* Infinite loop */
  for(;;)
  {
    osDelay(1);
  }
  /* USER CODE END StartGFXTask */
}

 /**
  * @brief  Period elapsed callback in non blocking mode
  * @note   This function is called  when TIM6 interrupt took place, inside
  * HAL_TIM_IRQHandler(). It makes a direct call to HAL_IncTick() to increment
  * a global variable "uwTick" used as application time base.
  * @param  htim : TIM handle
  * @retval None
  */
void HAL_TIM_PeriodElapsedCallback(TIM_HandleTypeDef *htim)
{
  if (htim->Instance == TIM6) {
    HAL_IncTick();
  }
}

void Error_Handler(void)
{
  __disable_irq();
  while (1)
  {
  }
}

/************************ (C) COPYRIGHT STMicroelectronics *****END OF FILE****/
